# CM85F register map
Registers are read-write, no defined reset value unless marked. A register's access mark holds for its fields unless they carry their own. Offsets are from the block's base; [hi:lo] are bit positions.

## FP_MVE — Floating-point and MVE Extension
Base 0xE000EF34
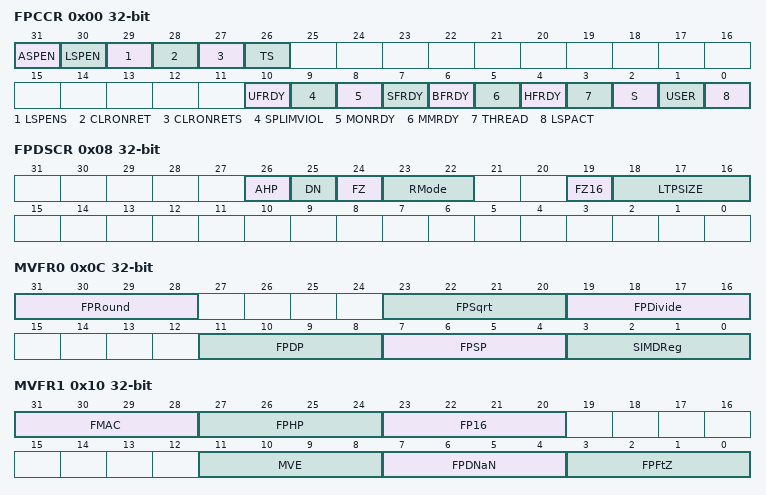
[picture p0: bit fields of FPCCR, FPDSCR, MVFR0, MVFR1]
0x00 FPCCR — Floating Point Context Control Register holds control data for the Floating Point Unit
  [31] ASPEN — Automatic state preservation enable
    0=Disable CONTROL.FPCA setting on execution of a floating-point instruction; 1=Enable CONTROL.FPCA setting on execution of a floating-point instruction
  [30] LSPEN — Automatic state preservation enable
    0=Disable automatic lazy context save; 1=Enable automatic lazy state preservation for floating-point context
  [29] LSPENS — Lazy state preservation enable Secure only
    0=LSPEN is readable and writeable from both Security states; 1=LSPEN is readable from both Security states. Writes to LSPEN are ignored from the Non-secure state
  [28] CLRONRET — Clear on return
    0=Disabled; 1=Enabled
  [27] CLRONRETS — Clear on return Secure only
    0=The CLRONRET field is accessibly from both Security states; 1=The Non-secure view of the CLRONRET field is read-only
  [26] TS — Treat as Secure
    0=Disabled; 1=Enabled
  [10] UFRDY — UsageFault ready
    0=Not able to set the UsageFault exception to pending; 1=Able to set the UsageFault exception to pending
  [9] SPLIMVIOL — Stack pointer limit violation
    0=The existing behavior is retained; 1=The memory accesses associated with the floating-point state preservation are not performed
  [8] MONRDY — DebugMonitor ready
    0=Not able to set the DebugMonitor exception to pending; 1=Able to set the DebugMonitor exception to pending
  [7] SFRDY — SecureFault ready
  [6] BFRDY — BusFault ready
    0=Not able to set the BusFault exception to pending; 1=Able to set the BusFault exception to pending
  [5] MMRDY — MemManage ready
    0=Not able to set the MemManage exception to pending; 1=Able to set the MemManage exception to pending
  [4] HFRDY — HardFault ready
    0=Not able to set the HardFault exception to pending; 1=Able to set the HardFault exception to pending
  [3] THREAD — Thread mode
    0=Handler mode; 1=Thread mode
  [2] S — Security status of the floating point context
    0=floating-point context belongs to the Non-secure state; 1=floating-point context belongs to the Secure state
  [1] USER — Indicates the privilege level of the software executing, when the processor allocated the floating point stack
    0=Privileged level; 1=Unprivileged level
  [0] LSPACT — Lazy state preservation active
    0=Lazy state preservation is not active; 1=Lazy state preservation is active
0x04 FPCAR — Floating Point Context Address Register holds the location of the unpopulated floating-point register space allocated on an exception stack frame
0x08 FPDSCR — Floating Point Default Status Control Register holds the default values for the floating-point status control data that the processor assigns to the FPSCR when it creates a new floating-point context
  [26] AHP — Default value for FPSCR.AHP
  [25] DN — Default value for FPSCR.DN
  [24] FZ — Default value for FPSCR.FZ
  [23:22] RMode — Default value for FPSCR.RMode
  [19] FZ16 — Default value for FPSCR.FZ16
  [18:16] LTPSIZE — Default value for FPSCR.LTPSIZE
0x0C MVFR0 ro — Media and FP Feature Register 0 describes the features provided by the Floating-point extension
  [31:28] FPRound — Floating-point rounding modes
    0=Rounding modes are not supported; 1=All rounding modes are supported
  [23:20] FPSqrt — Floating-point square root
    0=Floating-point square root not supported; 1=Floating-point square root is supported
  [19:16] FPDivide — Floating-point divide
    0=Floating-point divide operations are not supported; 1=Floating-point divide operations are supported
  [11:8] FPDP — Floating-point double-precision
    0=Floating-point double-precision operations are not supported; 2=Floating-point double-precision operations are not supported
  [7:4] FPSP — Floating-point single-precision
    0=Floating-point single-precision operations are not supported; 2=Floating-point single-precision operations are supported
  [3:0] SIMDReg — SIMD registers
    1=Supported, 16 x 64-bit registers
0x10 MVFR1 ro — Media and FP Feature Register 1 describes the features provided by the Floating-point extension
  [31:28] FMAC — Fused multiply accumulate instructions
    0=Fused multiply accumulate instructions are not supported; 1=Fused multiply accumulate instructions are supported
  [27:24] FPHP — Floating-point half-precision conversion
    0=Floating-point half-precision conversion instructions are not supported; 1=Half-precision to single-precision is implemented; 2=Half-precision to single and double-precision are implemented
  [23:20] FP16 — Floating-point half-precision data processing
    0=Floating-point half-precision data processing is not supported; 1=Floating-point half-precision data processing is supported
  [11:8] MVE — Indicates support for MVE
    0=MVE is not supported; 1=MVE is supported without Floating-point; 2=MVE is supported with single and double-precision Floating-point
  [7:4] FPDNaN — Floating-point default NaN
    1=Floating-point default NaN propagation is not supported; 1=Floating-point default NaN propagation is supported
  [3:0] FPFtZ — Floating-point flush-to-zero
    0=Floating-point flush-to-zero operations not supported; 1=Full denormalized numbers arithmetic supported
0x14 MVFR2 ro — Media and FP Feature Register 2 describes the features provided by the floating-point extension
  [7:4] FPMisc — Floating-point miscellaneous
    0=Floating-point extensions not implemented; 4=Selection, directed conversion to integer, VMINNM and MAXNM supported
